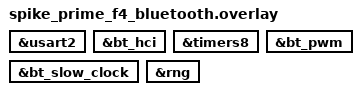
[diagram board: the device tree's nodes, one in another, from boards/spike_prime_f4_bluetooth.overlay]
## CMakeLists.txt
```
# SPDX-License-Identifier: Apache-2.0
cmake_minimum_required(VERSION 3.20.5)

list(APPEND DTS_ROOT ${CMAKE_CURRENT_SOURCE_DIR})
list(APPEND BOARD_ROOT ${CMAKE_CURRENT_SOURCE_DIR})
list(APPEND SYSCALL_INCLUDE_DIRS ${CMAKE_CURRENT_SOURCE_DIR}/sdk/include ${CMAKE_CURRENT_SOURCE_DIR}/include)
find_package(Zephyr REQUIRED HINTS $ENV{ZEPHYR_BASE})
project(brickphyr)
include(cmake/runtime_memory.cmake)

# Zephyr otherwise tracks its own Git index for both version headers.
# Use its application-version dependency hook, including in Git worktrees.
find_package(Git QUIET)
if(GIT_FOUND)
  execute_process(COMMAND ${GIT_EXECUTABLE} rev-parse --path-format=absolute
      --git-path index --git-path HEAD
    WORKING_DIRECTORY ${CMAKE_CURRENT_SOURCE_DIR}
    RESULT_VARIABLE revision_result OUTPUT_VARIABLE revision_dependencies
    OUTPUT_STRIP_TRAILING_WHITESPACE ERROR_QUIET)
  if(revision_result EQUAL 0)
    string(REPLACE "\n" ";" revision_dependencies "${revision_dependencies}")
    set_property(TARGET app_version_h PROPERTY APP_VERSION_DEPENDS ${revision_dependencies})
  endif()
endif()

target_sources(app PRIVATE src/main.c)
target_sources_ifdef(CONFIG_HWINFO app PRIVATE src/hub_reset.c)
target_sources_ifdef(CONFIG_BRICKPHYR_WATCHDOG app PRIVATE src/hub_watchdog.c)
target_sources_ifdef(CONFIG_BRICKPHYR_WATCHDOG_FIXTURE app PRIVATE tests/watchdog/fixture.c)
if(CONFIG_BRICKPHYR_PORTS)
  target_sources(app PRIVATE src/hub_ports.c)
  if(CONFIG_BRICKPHYR_MOTOR_OUTPUT_STM32)
    target_sources(app PRIVATE src/ports/output_stm32.c)
  else()
    target_sources(app PRIVATE src/ports/output.c)
  endif()
  target_include_directories(app PRIVATE ${WEST_TOPDIR}/pybricks-micropython/lib/lego)
endif()
if(CONFIG_BRICKPHYR_PORT_UART)
  target_sources(app PRIVATE src/ports/lump.c src/ports/uart.c src/ports/sensor.c src/ports/settings.c)
  include(cmake/pbio.cmake)
endif()
target_sources_ifdef(CONFIG_BRICKPHYR_BATTERY app PRIVATE src/hub_battery.c)
target_sources_ifdef(CONFIG_BRICKPHYR_CHARGER app PRIVATE src/hub_charger.c)
target_sources_ifdef(CONFIG_BRICKPHYR_USB_BC12 app PRIVATE src/host_usb_power.c)
if(CONFIG_BRICKPHYR_MOTOR_CONTROL)
  set(BRICKPHYR_ROOT ${CMAKE_CURRENT_SOURCE_DIR})
  include(cmake/motor_control.cmake)
endif()
target_sources_ifdef(CONFIG_BRICKPHYR_SOUND_STM32 app PRIVATE drivers/sound_stm32.c)
target_sources_ifdef(CONFIG_BRICKPHYR_CC2640_NPI app PRIVATE drivers/cc2640_npi.c)
if(CONFIG_BRICKPHYR_CC2640_CONTROL)
  include(cmake/cc2640.cmake)
endif()
if(CONFIG_BRICKPHYR_CC2640_BLE)
  include(cmake/pbio.cmake)
  target_sources(app PRIVATE src/host_cc2640.c src/host_ble_session.c
    src/host_transport.c src/host_protocol.c)
endif()
target_sources_ifdef(CONFIG_BRICKPHYR_CC2640_SMP app PRIVATE src/host_cc2640_smp.c)
target_sources_ifdef(CONFIG_BRICKPHYR_SOUND app PRIVATE src/hub_sound.c src/sound/waveform.c)
target_sources_ifdef(CONFIG_BRICKPHYR_MATRIX app PRIVATE src/hub_matrix.c src/hub_matrix_font.c)
target_sources_ifdef(CONFIG_BRICKPHYR_TELEMETRY app PRIVATE src/telemetry.c)
target_include_directories(app PRIVATE include sdk/include)

if(CONFIG_BRICKPHYR_IMU)
  set(BRICKPHYR_ROOT ${CMAKE_CURRENT_SOURCE_DIR})
  include(cmake/hub_imu.cmake)
endif()

if(CONFIG_BRICKPHYR_NATIVE)
  set(BRICKPHYR_ROOT ${CMAKE_CURRENT_SOURCE_DIR})
  include(sdk/native.cmake)
endif()

if(CONFIG_BOARD_SPIKE_PRIME_F4)
  include(cmake/pbio.cmake)
  if(CONFIG_BT_HCI_SETUP)
    target_sources(app PRIVATE drivers/ti_cc2564c.c src/hub_bluetooth.c
      src/host_ble.c src/host_ble_session.c)
    generate_inc_file_for_target(app
      ${WEST_TOPDIR}/modules/lib/ti-bt-service-packs/initscripts/TIInit_6.12.26.bts
      ${ZEPHYR_BINARY_DIR}/include/generated/ti_cc2564c_bts.inc)
  endif()
  target_sources(app PRIVATE src/host_usb.c src/host_transport.c src/host_protocol.c
    ${WEST_TOPDIR}/pybricks-micropython/lib/pbio/src/protocol/pybricks.c
    src/storage.c src/storage_mount.c
    drivers/input_resistor_ladder.c drivers/led_tlc5955.c)
  target_include_directories(app PRIVATE include ${WEST_TOPDIR}/pybricks-micropython/lib/pbio/include)
endif()

if(CONFIG_BRICKPHYR_HUB)
  target_sources(app PRIVATE src/hub.c src/hub_menu.c src/hub_light.c src/hub_power.c src/configuration.c)
  if(CONFIG_BOARD_SPIKE_PRIME_F4 AND CONFIG_BRICKPHYR_APP_STORAGE AND CONFIG_BRICKPHYR_MATRIX)
    target_sources(app PRIVATE src/hub_launcher.c)
  endif()
  add_custom_target(firmware_package
    COMMAND "${PYTHON_EXECUTABLE}" -m tools.package_firmware
            "${ZEPHYR_BINARY_DIR}" --version "${APP_VERSION_STRING}"
            --sdk "${ZEPHYR_SDK_INSTALL_DIR}"
    WORKING_DIRECTORY "${CMAKE_CURRENT_SOURCE_DIR}"
    DEPENDS zephyr_final
    USES_TERMINAL
    VERBATIM
  )
  if(TARGET brickphyr-build-record)
    add_dependencies(firmware_package brickphyr-build-record)
  endif()
endif()
```

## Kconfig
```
# SPDX-License-Identifier: Apache-2.0
mainmenu "Brickphyr"

# Firmware services use queues/events; the native API exposes no mailboxes.
# Do not reserve descriptors for an unused asynchronous mailbox subsystem.
config NUM_MBOX_ASYNC_MSGS
	default 0

# Control preempts storage, which preempts a busy primary. Hardware and management
# retain their priorities above all three; timers can defeat equal-priority slices.
config NUM_PREEMPT_PRIORITIES
	default 17 if BRICKPHYR_NATIVE

# Crypto temporaries share the system heap instead of a user-mapped libc arena.
config TF_PSA_CRYPTO_USER_CONFIG_FILE
	default "brickphyr/crypto_config.h" if BOARD_SPIKE_PRIME_F4 && MBEDTLS_BUILTIN && !MBEDTLS_ENABLE_HEAP

config HEAP_MEM_POOL_ADD_SIZE_BRICKPHYR_CRYPTO
	int
	default 2048 if MBEDTLS && TF_PSA_CRYPTO_USER_CONFIG_FILE = "brickphyr/crypto_config.h"
	default 0

# BC1.2 measures D+/D- before the USB PHY attaches to the host.
config CDC_ACM_SERIAL_ENABLE_AT_BOOT
	default n if BRICKPHYR_USB_BC12

# F4 UART reception cannot tolerate the bytewise size-optimized libc copies
# used by bounded snapshot/record critical sections. Keep firmware code at -Os.
config PICOLIBC_TOOLCHAIN_SPEED_OPTIMIZATIONS
	default y if BOARD_SPIKE_PRIME_F4

# Full source discovery with six controller observations exceeds the upstream
# 384-byte default (about 430 bytes including the SMP header on F4).
config MCUMGR_TRANSPORT_NETBUF_SIZE
	default 512 if BRICKPHYR_MOTOR_CONTROL && BRICKPHYR_TELEMETRY

# Command files use the standard SMP Shell handler on its existing worker.
# Leave room for the response map/header even with a 384-byte SMP buffer.
config SHELL_BACKEND_DUMMY_EXECUTE_ONLY
	default y if MCUMGR_GRP_SHELL

config SHELL_BACKEND_DUMMY_BUF_SIZE
	default 256 if MCUMGR_GRP_SHELL

config MCUMGR_TRANSPORT_NETBUF_USER_DATA_SIZE
	default 16 if BRICKPHYR_CC2640_SMP && 64BIT
	default 8 if BRICKPHYR_CC2640_SMP

# Unknown SMP fields must not bypass the decoder's bounded nesting and exhaust
# its 2 KiB worker stack. Current management fields need no deeper skipped value.
config ZCBOR_MAX_RECURSION_DEPTH
	default 4 if MCUMGR

# Management commands have no acquisition deadline. Keep CBOR/file processing
# below the 833 Hz IMU and 200 Hz motor service, but above Shell/applications.
config MCUMGR_TRANSPORT_WORKQUEUE_THREAD_PRIO
	default 10 if BRICKPHYR_IMU || BRICKPHYR_MOTOR_CONTROL

# Bluetooth needs the cooperative system queue; USB core and CDC processing
# must be preemptible by the 1.2 ms acquisition and 5 ms control work.
config USBD_THREAD_PREEMPTIBLE
	default y if BOARD_SPIKE_PRIME_F4

config USBD_CDC_ACM_WORKQUEUE
	default y if BOARD_SPIKE_PRIME_F4

config USBD_CDC_ACM_WORKQUEUE_PRIORITY
	default 8 if BOARD_SPIKE_PRIME_F4

# Python admission uses about 1 KiB in the GATT callback; the pinned F4 build's
# HCI/L2CAP/ATT call chain adds 696 bytes. Leave room for exception/error paths.
config BT_RX_STACK_SIZE
	default 2048 if BRICKPHYR_PYTHON

config TASK_WDT_MIN_TIMEOUT
	default 1000 if BRICKPHYR_WATCHDOG

config TASK_WDT_HW_FALLBACK_DELAY
	default 1000 if BRICKPHYR_WATCHDOG

config TASK_WDT_CHANNELS
	default 2 if BRICKPHYR_WATCHDOG

source "Kconfig.zephyr"

config BRICKPHYR_HUB
	bool
	default y if BOARD_SPIKE_PRIME_F4 || BOARD_TECHNIC_HUB

config BRICKPHYR_HOST_UART
	bool "UART management stream" if TEST
	depends on UART_INTERRUPT_DRIVEN
	default y if BOARD_SPIKE_PRIME_F4
	help
	  Enable the USB CDC/UART transport for the shared Shell and Pybricks
	  stream dispatcher. BLE management uses the same Shell independently;
	  UART support for wired devices does not require this endpoint.

config BRICKPHYR_CC2640_NPI
	bool "CC2640 SPI network-processor transport"
	depends on DT_HAS_TI_CC2640_NPI_ENABLED
	select GPIO
	select SPI
	select SPI_STM32_INTERRUPT if SOC_FAMILY_STM32
	help
	  Bounded SPI transport for the factory TI BLE stack on Technic Hub.
	  This does not enable advertising or a Bluetooth host endpoint.

config BRICKPHYR_CC2640_CONTROL
	bool "CC2640 controller and peripheral initialization"
	depends on BRICKPHYR_CC2640_NPI
	help
	  Use the TI protocol definitions and Pybricks startup sequence through NPI.
	  Includes peripheral GAP/GATT preparation and ATT handling. Enable
	  BRICKPHYR_CC2640_BLE to start the management endpoint at boot.

config BRICKPHYR_CC2640_BLE
	bool "CC2640 BLE management endpoint"
	depends on BRICKPHYR_CC2640_CONTROL && !BT
	depends on SHELL && MCUMGR_TRANSPORT_SHELL && SETTINGS_RUNTIME
	help
	  Run the factory TI peripheral stack on a dedicated worker and expose
	  the shared Pybricks identity and native Shell/SMP stream. This profile
	  has synthetic transport checks; physical Technic acceptance is pending.

config BRICKPHYR_CC2640_SMP
	bool "CC2640 SMP GATT transport"
	depends on MCUMGR && !BT
	depends on BRICKPHYR_CC2640_BLE || ZTEST
	default y if BRICKPHYR_CC2640_BLE
	select MCUMGR_TRANSPORT_REASSEMBLY
	help
	  Expose the standard MCUmgr BLE service through the factory TI stack.
	  Reuse Zephyr packet reassembly and command processing with the shared
	  management owner. This is independent of SMP over the Shell stream.

config BRICKPHYR_WATCHDOG
	bool "System progress watchdog"
	default y if BRICKPHYR_HUB
	depends on DT_HAS_ST_STM32_WATCHDOG_ENABLED || ARCH_POSIX
	select WATCHDOG
	select TASK_WDT
	select TASK_WDT_HW_FALLBACK
	select HWINFO
	help
	  Supervise initialization, the hub loop and system workqueue using
	  Zephyr Task Watchdog and an independent hardware fallback. The USB
	  powered off state continues supervision until a fresh button press.

config BRICKPHYR_WATCHDOG_TIMEOUT_MS
	int "Maximum interval without system progress (ms)"
	depends on BRICKPHYR_WATCHDOG
	default 3000
	range 100 10000

config BRICKPHYR_WATCHDOG_BOOT_TIMEOUT_MS
	int "Maximum initialization time after watchdog start (ms)"
	depends on BRICKPHYR_WATCHDOG
	default 10000
	range 100 30000

config BRICKPHYR_WATCHDOG_FIXTURE
	bool "Enable one-shot watchdog acceptance commands"
	depends on BRICKPHYR_WATCHDOG && SHELL
	help
	  Diagnostic image only. watchdog_test service stalls the system queue;
	  watchdog_test hardware also locks interrupts until the MCU resets.

config BRICKPHYR_PORTS
	bool "Powered Up port detection"
	default y if BOARD_SPIKE_PRIME_F4
	depends on DT_HAS_LEGO_POWERED_UP_PORTS_ENABLED
	select GPIO
	help
	  Detect empty, passive and UART ports using the Pybricks pin sequence
	  over Zephyr GPIO. The port service also owns sensor supply and coast.

config BRICKPHYR_PORT_UART
	bool "Powered Up UART messaging"
	default y if BOARD_SPIKE_PRIME_F4
	depends on BRICKPHYR_PORTS
	select SERIAL
	select UART_INTERRUPT_DRIVEN
	select UART_USE_RUNTIME_CONFIGURE
	select RING_BUFFER
	select SETTINGS
	select SETTINGS_RUNTIME
	select PINCTRL_NON_STATIC if PINCTRL
	select KERNEL_MEM_POOL
	help
	  Negotiate LUMP devices and acquire raw and converted sensor samples.
	  One worker owns GPIO, UART, measurement selection and recognized sensor
	  DC supply. Raw H-bridge access is not exposed.

config HEAP_MEM_POOL_ADD_SIZE_BRICKPHYR_PORT_UART
	int
	default $(add,2048,$(mul,5888,$(dt_node_enabled_child_count,$(dt_nodelabel_path,hub_ports)))) if BRICKPHYR_PORT_UART && !64BIT && SYS_HEAP_SMALL_ONLY && !SYS_HEAP_CANARIES
	default $(add,2048,$(mul,6144,$(dt_node_enabled_child_count,$(dt_nodelabel_path,hub_ports)))) if BRICKPHYR_PORT_UART
	help
	  UART state and mode descriptions use the shared heap only while a
	  UART device is connected. Budget 5888 bytes per enabled port on a
	  32-bit small heap without canaries: the current ARM link and sixteen
	  complete modes occupy 5760 bytes including allocation headers. Other configurations
	  retain 6 KiB per port. Both include another 2 KiB for negotiation growth.
	  Ordinary devices allocate only their advertised payloads. No allocation
	  occurs on the DATA path.

config BRICKPHYR_MOTORS
	bool "Powered Up direct motor drive"
	default y if BOARD_SPIKE_PRIME_F4
	depends on BRICKPHYR_PORTS
	select PWM
	help
	  Owned, asynchronous native/Shell duty, brake and coast commands through
	  the port service. Outputs stay in coast at boot; application cleanup and
	  device loss stop them.

config BRICKPHYR_MOTOR_CONTROL
	bool "Powered Up speed and position control"
	default y if BOARD_SPIKE_PRIME_F4
	depends on BRICKPHYR_MOTORS && BRICKPHYR_PORT_UART && BRICKPHYR_BATTERY
	help
	  Reuse PBIO models, observer and trajectories in the existing port owner.
	  A dedicated port queue services the 5 ms model step independently of
	  system work. Missing encoder/battery input or a missed frame coasts the
	  motor and reports an error. Physical timing and tuning are experimental.

config BRICKPHYR_MOTOR_OUTPUT_STM32
	bool
	default y if BOARD_SPIKE_PRIME_F4
	depends on BRICKPHYR_MOTORS && SOC_SERIES_STM32F4X
	select PINCTRL
	help
	  Exclusive F4 H-bridge timer backend with shared TIM2 reset/update edges.
	  The generic STM32 PWM driver must not own these timers simultaneously.

config HEAP_MEM_POOL_ADD_SIZE_BRICKPHYR_MOTOR_CONTROL
	int
	default $(mul,512,$(dt_node_enabled_child_count,$(dt_nodelabel_path,hub_ports))) if BRICKPHYR_MOTOR_CONTROL
	help
	  Controller state borrows from the shared heap when observation or
	  regulation is first requested. Budget 512 bytes per enabled port for
	  the controller, observer and allocation overhead. No allocation occurs
	  in control frames; the worker releases state after its lease ends.

config BRICKPHYR_BATTERY
	bool "Battery voltage, load-current and temperature observations"
	default y if BOARD_SPIKE_PRIME_F4 || BOARD_TECHNIC_HUB
	depends on DT_HAS_LEGO_ADC_BATTERY_ENABLED
	select ADC
	select GPIO if $(dt_nodelabel_has_prop,hub_battery,chemistry-gpios)
	select REQUIRES_FULL_LIBC if $(dt_nodelabel_array_prop_has_val,hub_battery,io-channel-names,temperature)
	help
	  Shared native/Shell/SMP snapshots from Zephyr ADC, using the board's
	  Pybricks scaling and optional pack thermistor. No charging control or
	  state-of-charge estimate.

config BRICKPHYR_CHARGER
	bool "Prime hub battery charger"
	default y if BOARD_SPIKE_PRIME_F4
	depends on DT_HAS_LEGO_PRIME_CHARGER_ENABLED
	select ADC
	select PWM
	help
	  MP2639A charging and observations using the shared TLC5955 frame and
	  Pybricks current presets. Standard USB charging requires configuration;
	  dedicated charger detection is a separate USB BC1.2 capability.

config BRICKPHYR_USB_BC12
	bool "USB charger source detection"
	default y if BOARD_SPIKE_PRIME_F4
	depends on BRICKPHYR_CHARGER && USB_BC12
	depends on CDC_ACM_SERIAL_INITIALIZE_AT_BOOT
	help
	  Detect the source before attaching the existing CDC device. The hub
	  power loop handles cable changes, including USB-powered shutdown.

config BRICKPHYR_SOUND
	bool "Hub tone and PCM service"
	default y if BOARD_SPIKE_PRIME_F4
	help
	  One speaker owner, firmware-owned DMA samples and bounded PCM queue.
	  Native applications and the USB/BLE Shell use the same service.

config BRICKPHYR_SOUND_STM32
	bool "Prime F4 DAC sound output"
	default y if BOARD_SPIKE_PRIME_F4
	depends on BRICKPHYR_SOUND
	depends on DT_HAS_LEGO_PRIME_F4_SPEAKER_ENABLED && SOC_SERIES_STM32F4X
	depends on TIMER_HAS_64BIT_CYCLE_COUNTER
	select DMA
	select GPIO
	select PINCTRL
	select RESET
	help
	  Timer-triggered DAC samples through Zephyr DMA. The driver owns DAC1
	  channel 1, TIM6 and the speaker amplifier; no sound starts at boot.

config BRICKPHYR_IMU
	bool "Hub IMU acquisition and orientation"
	default y if BOARD_SPIKE_PRIME_F4
	depends on DT_HAS_ST_LSM6DS3TR_C_ENABLED && TIMER_HAS_64BIT_CYCLE_COUNTER
	select I2C
	select GPIO
	help
	  One bounded worker uses the ST/Pybricks register API and ported
	  calibration/orientation algorithms. Native applications and telemetry
	  share read-only snapshots; calibration uses Zephyr Settings.

config BRICKPHYR_TELEMETRY
	bool "Read-only hub observations"
	default y if BOARD_SPIKE_PRIME_F4
	depends on MCUMGR && SHELL
	select MCUMGR_SMP_CBOR_MIN_DECODING_LEVEL_2
	select MCUMGR_SMP_CBOR_MIN_ENCODING_LEVEL_2 if ZCBOR_CANONICAL
	select MCUMGR_SMP_CBOR_MIN_ENCODING_LEVEL_1
	select CBPRINTF_FP_SUPPORT if BRICKPHYR_PORT_UART
	help
	  On-demand snapshots through SMP and the shared shell. No background
	  transmission, sensor reconfiguration or application lifecycle work.

config BRICKPHYR_MATRIX
	bool "Hub light matrix"
	default y
	depends on DT_HAS_LEGO_HUB_MATRIX_ENABLED && LED
	help
	  Shared 5 by 5 display, with application and terminal ownership.

config BRICKPHYR_LIGHT
	bool "Application access to hub button lighting"
	default y
	depends on (DT_HAS_TI_TLC5955_ENABLED && LED) || (DT_HAS_LEGO_HUB_PWM_RGB_ENABLED && PWM)
	help
	  Shared system indication and application colors on the hub buttons.
	  The base readiness indication remains available without this API.

config BRICKPHYR_NATIVE
	bool "Experimental protected native applications"
	depends on CPU_CORTEX_M && USERSPACE && ARM_MPU && LLEXT
	depends on LLEXT_HEAP_SYSTEM && LLEXT_IMPORT_ALL_GLOBALS
	depends on !CURRENT_THREAD_USE_TLS && !USERSPACE_THREAD_MAY_RAISE_PRIORITY
	depends on LOG && LOG_MODE_DEFERRED
	select LOG_OUTPUT
	select THREAD_STACK_INFO
	select INIT_STACKS
	select THREAD_MONITOR
	select THREAD_NAME
	select SYS_HEAP_RUNTIME_STATS
	select DYNAMIC_THREAD
	select DYNAMIC_THREAD_ALLOC
	help
	  One separately built application, with a compatible versioned SDK.

config BRICKPHYR_APP_PACKAGES
	bool "Composite application packages" if !BRICKPHYR_PYTHON
	depends on (BRICKPHYR_NATIVE || BRICKPHYR_PYTHON) && ZCBOR
	default y
	help
	  Read one file map containing a primary, native controllers and resources.
	  Python requires its file-map reader. Native-only profiles may omit it
	  while retaining standalone ELF applications and the same native ABI.

config BRICKPHYR_CAPTURE
	bool "Built-in finite RAM observations"
	depends on BRICKPHYR_NATIVE && BRICKPHYR_TELEMETRY && SHELL
	default y if BOARD_SPIKE_PRIME_F4 || TEST
	help
	  Record selected passive observations through the shared recorder and SMP.
	  Buffer and sampling stack are allocated only for an explicit capture.
	  With motor support, attach finite grouped actions using the same Shell.
	  Scheduled drive stops on cancellation, failure or management disconnect.

config BRICKPHYR_NATIVE_FIXTURES
	bool "Embed native lifecycle test images"
	depends on BRICKPHYR_NATIVE
	help
	  Board acceptance fixture; not an application upload mechanism.

config LLEXT_EXPORT_SYMBOL_GROUP_BRICKPHYR
	bool
	default y if BRICKPHYR_NATIVE

config BRICKPHYR_APPLICATION_STACK_SIZE
	int "Maximum application stack bytes"
	depends on BRICKPHYR_NATIVE
	default 12288 if BRICKPHYR_PYTHON
	default 2048
	range 2048 32768
	help
	  Admission limit for native ABI requirements and explicit Python stack
	  requests. The default Python stack is configured separately.
	  Stacks are allocated only while an application is loaded, rounded for
	  MPU protection, with a 2048-byte minimum for the native entry/exit path.
	  Python compilation and exception reporting require more stack than the
	  minimal native entry; measure high-water use.

config BRICKPHYR_APPLICATION_IMAGE_SIZE
	int "Maximum uploaded application bytes"
	default 32768
	range 1024 65536
	help
	  Admission limit, not a reservation. A RAM upload also needs this much
	  free system heap alongside the loaded program and its stack.

config BRICKPHYR_NATIVE_MEMORY_SIZE
	int "Native image execution memory limit"
	default 65536
	range 8192 262144
	help
	  Bounds each native image's admitted region and loader metadata cost.
	  Individual allocations use the system heap; loading and stack allocation
	  can still fail if it lacks sufficiently large aligned free blocks.

config BRICKPHYR_PYTHON
	bool "Experimental MicroPython engine"
	depends on BRICKPHYR_NATIVE || (TEST && (ARCH_POSIX || (CPU_CORTEX_M && USERSPACE)))
	depends on ZCBOR
	help
	  MicroPython core with source compilation, bytecode loading and GC.
	  Host integration and Pybricks bindings are under development.

config BRICKPHYR_PYTHON_HEAP_SIZE
	int "Python execution arena bytes"
	depends on BRICKPHYR_PYTHON && BRICKPHYR_NATIVE
	default 65536
	range 8192 262144
	help
	  Allocated from the system heap only while Python runs and released after
	  its thread is joined. Must be a power of two for MPU size/alignment.
	  This does not limit native ELF regions or reserve memory for idle Python.

config BRICKPHYR_PYTHON_STACK_SIZE
	int "Default Python stack bytes"
	depends on BRICKPHYR_PYTHON && BRICKPHYR_NATIVE
	default 12288
	range 4096 BRICKPHYR_APPLICATION_STACK_SIZE
	help
	  Used when a Python launch does not request a stack size. The shared
	  maximum application stack limit still applies to explicit requests.

config BRICKPHYR_PYBRICKS
	bool "Experimental Pybricks Python library"
	depends on BRICKPHYR_PYTHON
	default y
	help
	  Reuse the reference Python bindings over the shared runtime and
	  device services. Current coverage is listed in docs/compatibility.md.

config BRICKPHYR_PYBRICKS_EXECUTION
	bool "Pybricks client execution adapter"
	depends on BRICKPHYR_PYTHON && BRICKPHYR_NATIVE
	default y if BRICKPHYR_PYBRICKS
	help
	  Upload, run, interrupt and exchange application data through the
	  Pybricks USB/BLE protocol. Native SMP, Shell and REPL do not require
	  this adapter. Without it the protocol reports no execution capabilities.

config BRICKPHYR_APP_STORAGE
	bool "Installed native applications in LittleFS"
	depends on BRICKPHYR_NATIVE && FILE_SYSTEM_LITTLEFS && FLASH_MAP
	depends on DT_HAS_FIXED_PARTITIONS_ENABLED
	depends on FILE_SYSTEM_MKFS
	depends on !MCUMGR || MCUMGR_GRP_FS_FILE_ACCESS_HOOK
	select MCUMGR_SMP_VERBOSE_ERR_RESPONSE if MCUMGR

config BRICKPHYR_RADIO
	bool "Application BLE observations"
	depends on BRICKPHYR_NATIVE && BT && BT_PERIPHERAL && BT_OBSERVER
	default y
	help
	  Observe Pybricks broadcasts through the same Zephyr radio as management.
	  Only requested channels allocate storage; applications get copied samples.

config BRICKPHYR_BLE_PEER
	bool "Application BLE peripherals"
	depends on BRICKPHYR_RADIO && BT_CENTRAL && BT_GATT_CLIENT && BT_MAX_CONN >= 2
	default y
	help
	  One LEGO Wireless Protocol v3 or Xbox HID peer alongside management.
	  Discovery and ATT use the existing radio workqueue. Pairing additionally
	  requires BT_SMP; notification buffers are allocated per application lease.

config BRICKPHYR_HUB_NETWORK
	bool "Application Classic hub network"
	depends on BRICKPHYR_RADIO && BT_CLASSIC && BT_MAX_CONN >= 4
	default y
	help
	  Pybricks star networking over Classic L2CAP, alongside BLE management.
	  Kernel-owned per-source inboxes and relay queues are allocated on demand.

config BRICKPHYR_PYBRICKS_SLOTS
	int "Persistent Pybricks program slots"
	depends on BRICKPHYR_PYBRICKS_EXECUTION && BRICKPHYR_APP_STORAGE && SHELL
	range 0 128
	default 5 if BOARD_SPIKE_PRIME_F4
	default 0
	help
	  Map client slots to reserved names in the common application store.
	  They share its free space with named applications. Zero keeps the
	  RAM-only adapter. Native temporary uploads never write this store.
```

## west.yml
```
# SPDX-License-Identifier: Apache-2.0
manifest:
  version: "1.2"
  projects:
    - name: zcbor
      url: https://github.com/alepoydes/zcbor
      revision: f4b3f6975ea28c6f9e664d982710819759816d5b # Bounded unknown-field recursion
      path: modules/lib/zcbor
    - name: ti-bt-service-packs
      url: https://git.ti.com/git/ti-bt/service-packs.git
      revision: 3aa1d75f3c2ae77f6e4d36194e3d281b899ab149
      path: modules/lib/ti-bt-service-packs
    - name: pybricksdev
      url: https://github.com/alepoydes/pybricksdev
      revision: 973fe51b8960c3cac53ce56bed6129f0574c3919
    - name: pybricks
      url: https://github.com/alepoydes/pybricks-micropython
      revision: f3bdff45f3b7521b064e8aa8fb82068323aba880 # Brickphyr integration on v4.1.0b6
      path: pybricks-micropython
      # Initialize only micropython with Git; west recursively fetches unused ports.
    - name: zephyr
      url: https://github.com/alepoydes/zephyr
      revision: 0177626fb33513ca7b18834796c00be27c67c775 # Brickphyr integration on v4.4.2
      import:
        name-allowlist:
          - cmsis_6
          - cmsis-dsp
          - hal_stm32
          - littlefs
          - zcbor
          - mbedtls
          - tf-psa-crypto
  self:
    path: brickphyr
```

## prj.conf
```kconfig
# SPDX-License-Identifier: Apache-2.0
CONFIG_SHELL=y
CONFIG_SHELL_MINIMAL=y
CONFIG_SHELL_HELP=y
CONFIG_SHELL_ARGC_MAX=32
CONFIG_SHELL_BACKEND_SERIAL=y
CONFIG_SHELL_VT100_COLORS=n
CONFIG_SHELL_VT100_COMMANDS=y
CONFIG_SHELL_METAKEYS=y
CONFIG_SHELL_HISTORY=y
CONFIG_SHELL_HISTORY_BUFFER=512
CONFIG_SHELL_TAB=y
CONFIG_SHELL_TAB_AUTOCOMPLETION=y
CONFIG_SHELL_CMDS=y
CONFIG_SHELL_CMDS_RESIZE=y
CONFIG_SHELL_ECHO_STATUS=y
CONFIG_BOOT_BANNER=n
CONFIG_REBOOT=y
```

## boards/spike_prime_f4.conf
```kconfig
# SPDX-License-Identifier: Apache-2.0
# One owner for the CDC data pipe. Shell output never enters the Pybricks stream.
CONFIG_SHELL_BACKEND_SERIAL=n
CONFIG_UART_CONSOLE=n
CONFIG_SHELL_LOG_BACKEND=n
# Diagnostics has one retained sink and no runtime level controls.
CONFIG_LOG_RUNTIME_FILTERING=n
CONFIG_LOG_MAX_LEVEL=2
# Share message packaging code; these warnings/errors are not a hot data path.
CONFIG_LOG_ALWAYS_RUNTIME=y
CONFIG_UART_INTERRUPT_DRIVEN=y
CONFIG_USBD_VREQ_SUPPORT=y
CONFIG_CONSOLE=n
CONFIG_SETTINGS=y
CONFIG_SETTINGS_RUNTIME=y
CONFIG_FLASH=y
CONFIG_FLASH_MAP=y
CONFIG_FLASH_PAGE_LAYOUT=y
CONFIG_FLASH_JESD216_API=y
CONFIG_SPI_NOR_SFDP_RUNTIME=y
CONFIG_SPI_NOR_FLASH_LAYOUT_PAGE_SIZE=4096
CONFIG_FILE_SYSTEM=y
CONFIG_FILE_SYSTEM_LITTLEFS=y
CONFIG_FILE_SYSTEM_MKFS=y
# LittleFS receives caller buffers; Bluetooth crypto uses the shared system heap.
CONFIG_COMMON_LIBC_MALLOC_ARENA_SIZE=0
CONFIG_SETTINGS_FILE=y
CONFIG_SETTINGS_FILE_PATH="/settings/values"
# Boot filesystem work exceeds 1 KiB. Settings compaction nests filesystem
# metadata commits below Shell; give that complete call path a 4 KiB stack.
CONFIG_MAIN_STACK_SIZE=2048
# The 20 ms UI/power loop must yield to 833 Hz IMU acquisition (5) and
# the 5 ms port service (6), including their I/O completion wakeups.
CONFIG_MAIN_THREAD_PRIORITY=7
CONFIG_SHELL_STACK_SIZE=4096
# Observe every DTR edge before the next SET_CONTROL_LINE_STATE can change it.
CONFIG_USBD_MSG_DEFERRED_MODE=n

# Standard SMP framing shares the management stream with the interactive shell.
CONFIG_NET_BUF=y
CONFIG_ZCBOR=y
CONFIG_BASE64=y
CONFIG_CRC=y
CONFIG_MCUMGR=y
CONFIG_SHELL_BACKEND_DUMMY=y
CONFIG_MCUMGR_GRP_SHELL=y
CONFIG_MCUMGR_TRANSPORT_SHELL=y
CONFIG_MCUMGR_GRP_OS=y
CONFIG_MCUMGR_GRP_OS_MCUMGR_PARAMS=y
CONFIG_MCUMGR_GRP_SETTINGS=y
CONFIG_MCUMGR_MGMT_NOTIFICATION_HOOKS=y
CONFIG_MCUMGR_SMP_COMMAND_STATUS_HOOKS=y
CONFIG_MCUMGR_GRP_SETTINGS_ACCESS_HOOK=y
```

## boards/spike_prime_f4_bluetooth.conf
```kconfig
# SPDX-License-Identifier: Apache-2.0
# Optional BLE management; automatically advertises after boot.
CONFIG_BT=y
CONFIG_BT_PERIPHERAL=y
CONFIG_BT_OBSERVER=y
CONFIG_BT_CENTRAL=y
CONFIG_BT_SETTINGS=n
CONFIG_BT_DEVICE_NAME="Brickphyr"
# Full-size HCI commands in TI's service pack.
CONFIG_BT_BUF_CMD_TX_SIZE=255
CONFIG_TEST_RANDOM_GENERATOR=n
CONFIG_ENTROPY_DEVICE_RANDOM_GENERATOR=y
CONFIG_PSA_CSPRNG_GENERATOR=y
# One computer management link and one application LEGO peer.
CONFIG_BT_MAX_CONN=2
CONFIG_BT_SMP=y
# Older LEGO peripherals use LE legacy pairing.
CONFIG_BT_SMP_SC_PAIR_ONLY=n
# Keep both live links' keys; replace unused bonds in RAM for the next peer.
CONFIG_BT_MAX_PAIRED=2
CONFIG_BT_KEYS_OVERWRITE_OLDEST=y
# Fit terminal writes and binary SMP fragments without increasing controller
# packets; Zephyr fragments ATT messages for the CC2564C's 27-byte ACL limit.
CONFIG_BT_GATT_CLIENT=y
CONFIG_BT_GATT_AUTO_UPDATE_MTU=y
CONFIG_BT_L2CAP_TX_MTU=247
CONFIG_BT_BUF_ACL_RX_SIZE=251
# A 244-byte ATT notification needs ten 27-byte ACL fragments on CC2564C,
# queued over successive connection events with the five transmit buffers.
CONFIG_BT_BUF_ACL_TX_COUNT=5
CONFIG_BT_CONN_TX_MAX=5
CONFIG_BT_DATA_LEN_UPDATE=n
# Leave airtime for an application peer beside management traffic. On Inventor
# F4, a 7.5 ms management interval caused Xbox supervision timeouts; 15 ms
# supports simultaneous input and telemetry. Keep peripheral latency zero.
CONFIG_BT_PERIPHERAL_PREF_MIN_INT=12
CONFIG_BT_PERIPHERAL_PREF_MAX_INT=12
CONFIG_BT_PERIPHERAL_PREF_LATENCY=0
# Request the preference immediately if the central initially chooses 7.5 ms.
# Zephyr's default five-second delay exceeds the Xbox's three-second timeout.
CONFIG_BT_CONN_PARAM_UPDATE_TIMEOUT=0
CONFIG_MCUMGR_TRANSPORT_BT=y
# Application peer pairing must not change the existing host management access.
CONFIG_MCUMGR_TRANSPORT_BT_PERM_RW=y
CONFIG_MCUMGR_TRANSPORT_BT_REASSEMBLY=y
# Active SMP and idle links use the same preference. The central still chooses
# the actual interval; SMP must not restore the conflicting 7.5 ms setting.
CONFIG_MCUMGR_TRANSPORT_BT_CONN_PARAM_CONTROL=y
CONFIG_MCUMGR_TRANSPORT_BT_CONN_PARAM_CONTROL_MIN_INT=12
CONFIG_MCUMGR_TRANSPORT_BT_CONN_PARAM_CONTROL_MAX_INT=12
# BLE executes the same Settings/LittleFS path measured above 2 KiB on Shell.
CONFIG_MCUMGR_TRANSPORT_WORKQUEUE_STACK_SIZE=4096
```

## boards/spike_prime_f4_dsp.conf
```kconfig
# SPDX-License-Identifier: Apache-2.0
# Build selected upstream routines for firmware and the optional native SDK.
CONFIG_CMSIS_DSP=y
CONFIG_CMSIS_DSP_FILTERING=y
```

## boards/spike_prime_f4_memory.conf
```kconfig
# SPDX-License-Identifier: Apache-2.0
# Optional diagnostics: Zephyr kernel commands include an immediate reboot.
CONFIG_KERNEL_SHELL=y
CONFIG_SYS_HEAP_RUNTIME_STATS=y
```

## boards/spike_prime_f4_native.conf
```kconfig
# SPDX-License-Identifier: Apache-2.0
CONFIG_ZCBOR=y
CONFIG_BRICKPHYR_NATIVE=y
CONFIG_LLEXT=y
CONFIG_LLEXT_TYPE_ELF_RELOCATABLE=y
CONFIG_LLEXT_HEAP_SYSTEM=y
CONFIG_LLEXT_IMPORT_ALL_GLOBALS=y
CONFIG_LLEXT_EXPORT_DEFAULT_GROUPS=n
CONFIG_LLEXT_EDK_USERSPACE_ONLY=y
# Keep the three dynamic MPU regions for text/constants, data and BSS.
# Native images have no TLS; user entry queries its thread ID through SVC.
CONFIG_CURRENT_THREAD_USE_TLS=n
# F4 SRAM has no reserved prefix; keep static user stacks before ordinary data.
CONFIG_USERSPACE_STACKS_EARLY=y
# Shared by connected-device state, uploads and native loader allocations.
# Fit linked state, including capture/management and the storage worker.
# Python profiles override this shared-heap budget.
CONFIG_HEAP_MEM_POOL_SIZE=221696
# One active request, one queued request and the response retain independent
# buffers. Larger compact blocks reduce BLE request turns for 512 B more pool.
CONFIG_MCUMGR_TRANSPORT_NETBUF_COUNT=3
CONFIG_MCUMGR_TRANSPORT_NETBUF_SIZE=1536
CONFIG_BRICKPHYR_APPLICATION_IMAGE_SIZE=65536
CONFIG_BRICKPHYR_NATIVE_MEMORY_SIZE=214144
CONFIG_BRICKPHYR_APPLICATION_STACK_SIZE=16384
CONFIG_INIT_STACKS=y
CONFIG_THREAD_STACK_INFO=y
# Permission storage covers firmware threads and the protected application.
CONFIG_MAX_THREAD_BYTES=3
CONFIG_MCUMGR_GRP_OS_RESET_HOOK=y
# Essential services must preempt a native busy loop without relying on slices.
CONFIG_SHELL_THREAD_PRIORITY_OVERRIDE=y
CONFIG_SHELL_THREAD_PRIORITY=13
CONFIG_LOG_PROCESS_THREAD_CUSTOM_PRIORITY=y
CONFIG_LOG_PROCESS_THREAD_PRIORITY=13
# Application status includes resource accounting and supported formats.
CONFIG_MCUMGR_SMP_CBOR_MAX_MAIN_MAP_ENTRIES=24
CONFIG_BRICKPHYR_APP_STORAGE=y
# Startup mounts LittleFS and loads user data on the main stack. Keep the
# filesystem-call budget even though saves now run on the storage worker.
CONFIG_MAIN_STACK_SIZE=4096
# ELF validation nests filesystem reads on the SMP worker.
CONFIG_MCUMGR_TRANSPORT_WORKQUEUE_STACK_SIZE=4096
CONFIG_MCUMGR_GRP_FS=y
CONFIG_MCUMGR_GRP_FS_FILE_ACCESS_HOOK=y
```

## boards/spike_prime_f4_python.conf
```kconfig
# SPDX-License-Identifier: Apache-2.0
# Add to the native profile: both engines use the same application supervisor.
CONFIG_BRICKPHYR_PYTHON=y
# Reclaim the former 64 KiB Python reservation and Classic stack capacity into
# the shared heap. Active engines allocate arenas, native regions and stacks
# alongside uploads. The optional Classic fragment sets its smaller budget.
CONFIG_HEAP_MEM_POOL_SIZE=217600
CONFIG_BRICKPHYR_APPLICATION_IMAGE_SIZE=65536
CONFIG_BRICKPHYR_PYTHON_HEAP_SIZE=65536
```

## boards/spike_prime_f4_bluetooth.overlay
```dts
/* SPDX-License-Identifier: Apache-2.0 */
&usart2 { status = "okay"; };
&bt_hci { status = "okay"; };
&timers8 { status = "okay"; };
&bt_pwm { status = "okay"; };
&bt_slow_clock { status = "okay"; };
&rng { status = "okay"; };
```

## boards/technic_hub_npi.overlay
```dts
// SPDX-License-Identifier: Apache-2.0
&bt_reset { status = "disabled"; };
&spi1 { status = "okay"; };
&cc2640 { status = "okay"; };
```

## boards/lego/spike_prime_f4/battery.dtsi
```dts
// SPDX-License-Identifier: Apache-2.0
#include <zephyr/dt-bindings/adc/adc.h>

/* Pybricks prime_hub_f4/platform.c and pbdrvconfig.h at a7b1b04ae.
 * These are physical ADC channels, not PBIO's indices into its DMA buffer.
 */
/ {
	hub_battery: battery {
		compatible = "lego,adc-battery";
		io-channels = <&adc1 10>, <&adc1 11>, <&adc1 8>;
		io-channel-names = "current", "voltage", "temperature";
		chemistry = "li-ion";
		current-full-scale-ma = <7300>;
		voltage-full-scale-mv = <9900>;
		voltage-correction-microohms = <187500>;
	};
};

&adc1 {
	channel@8 {
		reg = <8>;
		zephyr,gain = "ADC_GAIN_1";
		zephyr,reference = "ADC_REF_INTERNAL";
		zephyr,acquisition-time = <ADC_ACQ_TIME(ADC_ACQ_TIME_TICKS, 15)>;
		zephyr,resolution = <12>;
	};
	channel@a {
		reg = <10>;
		zephyr,gain = "ADC_GAIN_1";
		zephyr,reference = "ADC_REF_INTERNAL";
		zephyr,acquisition-time = <ADC_ACQ_TIME(ADC_ACQ_TIME_TICKS, 15)>;
		zephyr,resolution = <12>;
	};
	channel@b {
		reg = <11>;
		zephyr,gain = "ADC_GAIN_1";
		zephyr,reference = "ADC_REF_INTERNAL";
		zephyr,acquisition-time = <ADC_ACQ_TIME(ADC_ACQ_TIME_TICKS, 15)>;
		zephyr,resolution = <12>;
	};
};
```

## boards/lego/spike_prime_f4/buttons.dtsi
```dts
// SPDX-License-Identifier: Apache-2.0

#include <zephyr/dt-bindings/input/input-event-codes.h>
#include <zephyr/dt-bindings/adc/adc.h>

/* Pybricks resistor values and ladder-1 thresholds. With charging disabled,
 * the observed center voltage is 3141..3147, on the ladder-0 cutoff of 3142.
 * Use the nominal ladder cutoffs here; reassess when adding charger control.
 */
/ {
	center_keys: center-keys {
		compatible = "lego,resistor-ladder";
		io-channels = <&adc1 14>;
		thresholds = <3872 3394 3009 2755 2538 2327 2141 1969>;
		key-codes = <0 INPUT_KEY_ENTER 0>;
	};
	arrow_keys: arrow-keys {
		compatible = "lego,resistor-ladder";
		io-channels = <&adc1 1>;
		thresholds = <3872 3394 3009 2755 2538 2327 2141 1969>;
		key-codes = <INPUT_KEY_LEFT INPUT_KEY_RIGHT INPUT_KEY_BLUETOOTH>;
	};
};

&adc1 {
	#address-cells = <1>;
	#size-cells = <0>;

	channel@1 {
		reg = <1>;
		zephyr,gain = "ADC_GAIN_1";
		zephyr,reference = "ADC_REF_INTERNAL";
		zephyr,acquisition-time = <ADC_ACQ_TIME(ADC_ACQ_TIME_TICKS, 15)>;
		zephyr,resolution = <12>;
	};
	channel@e {
		reg = <14>;
		zephyr,gain = "ADC_GAIN_1";
		zephyr,reference = "ADC_REF_INTERNAL";
		zephyr,acquisition-time = <ADC_ACQ_TIME(ADC_ACQ_TIME_TICKS, 15)>;
		zephyr,resolution = <12>;
	};
};
```

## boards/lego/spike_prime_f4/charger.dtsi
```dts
// SPDX-License-Identifier: Apache-2.0
/ {
	hub_charger: charger {
		compatible = "lego,prime-charger";
		mode-controller = <&hub_leds>;
		mode-channel = <14>;
		pwms = <&charger_pwm 1 10417 PWM_POLARITY_NORMAL>;
		io-channels = <&adc1 3>;
		status-ladder = <&center_keys>;
		status-bit = <2>;
	};
};

&timers5 {
	status = "okay";
	charger_pwm: pwm {
		pinctrl-0 = <&tim5_ch1_pa0>;
		pinctrl-names = "default";
		status = "okay";
	};
};

&adc1 {
	channel@3 {
		reg = <3>;
		zephyr,gain = "ADC_GAIN_1";
		zephyr,reference = "ADC_REF_INTERNAL";
		zephyr,acquisition-time = <ADC_ACQ_TIME(ADC_ACQ_TIME_TICKS, 15)>;
		zephyr,resolution = <12>;
	};
};
```

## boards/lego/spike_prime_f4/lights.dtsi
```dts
/* SPDX-License-Identifier: Apache-2.0 */
/ {
	hub_matrix: matrix {
		compatible = "lego,hub-matrix";
		led-controller = <&hub_leds>;
		/* Pybricks prime_hub_f4 LED_ARRAY_DEV_0_LIGHT_MATRIX wiring. */
		channels = <38 36 41 46 33
			    37 28 39 47 21
			    24 29 31 45 23
			    26 27 32 34 22
			    25 40 30 35 9>;
	};
};
&hub_leds {
	/* Provisional gains from visual RGB-pair checks on Inventor F4. */
	white-balance = <255 47 64>;
	status_top: status-top { channels = <5 4 3>; };
	status_bottom: status-bottom { channels = <8 7 6>; };
	bluetooth_led: bluetooth { channels = <20 19 18>; };
};
```

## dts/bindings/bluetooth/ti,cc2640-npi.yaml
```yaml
# SPDX-License-Identifier: Apache-2.0
description: TI CC2640 factory network processor using SPI NPI
compatible: "ti,cc2640-npi"
include: spi-device.yaml
properties:
  reset-gpios:
    type: phandle-array
    required: true
    description: Active-low reset, released to input after the startup pulse
  mrdy-gpios:
    type: phandle-array
    required: true
    description: Active-low host ready output
  srdy-gpios:
    type: phandle-array
    required: true
    description: Active-low controller ready input with pull-up and both-edge IRQ
```

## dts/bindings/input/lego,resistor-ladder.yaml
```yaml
# SPDX-License-Identifier: Apache-2.0
# Thresholds use the Pybricks three-input resistor-ladder decoder.
description: LEGO three-input resistor ladder
compatible: "lego,resistor-ladder"
include: base.yaml
properties:
  io-channels:
    type: phandle-array
    required: true
  thresholds:
    type: array
    required: true
    description: Eight descending thresholds in raw 12-bit ADC counts.
  key-codes:
    type: array
    required: true
    description: Three input codes in resistor order; zero skips a non-button input.
  sample-period-ms:
    type: int
    default: 10
```

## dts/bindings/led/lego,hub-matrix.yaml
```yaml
# SPDX-License-Identifier: Apache-2.0
description: LEGO hub 5 by 5 monochrome matrix on a shared TLC5955
compatible: "lego,hub-matrix"
properties:
  led-controller:
    type: phandle
    required: true
  channels:
    type: array
    required: true
    description: 25 TLC5955 wire channel indices, row-major in the hub's upright orientation.
```

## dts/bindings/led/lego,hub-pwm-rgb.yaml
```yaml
# SPDX-License-Identifier: Apache-2.0
description: Hub status RGB light driven by three timer PWM channels
compatible: "lego,hub-pwm-rgb"
include: base.yaml
properties:
  pwms:
    type: phandle-array
    required: true
    description: Red, green and blue channels, in that order
  white-balance:
    type: array
    required: true
    description: Linear red, green and blue PWM weights, each from 0 to 255
```

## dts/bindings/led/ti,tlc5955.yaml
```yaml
# SPDX-License-Identifier: Apache-2.0
description: TI TLC5955 LED controller with an external grayscale clock
compatible: "ti,tlc5955"
include: spi-device.yaml
properties:
  white-balance:
    type: array
    description: RGB duty weights (0..255) for the attached LEDs at logical white.
  latch-gpios:
    type: phandle-array
    required: true
  pwms:
    type: phandle-array
    required: true
    description: External GSCLK; the period must be exactly representable by the timer.
  initial-full-channels:
    type: array
    description: Non-LED channels initialized at full duty and reserved from LED writes.
child-binding:
  properties:
    channels:
      type: array
      required: true
      description: RGB channel indices in the Pybricks wire ordering (0..47).
```

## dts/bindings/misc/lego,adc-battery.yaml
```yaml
# SPDX-License-Identifier: Apache-2.0
description: LEGO battery voltage, load current and optional 103AT thermistor
compatible: "lego,adc-battery"
include: base.yaml
properties:
  io-channels:
    required: true
  io-channel-names:
    required: true
    description: Separate 12-bit inputs named current and voltage, and optional temperature.
  chemistry:
    type: string
    required: true
    enum: [unknown, alkaline, li-ion]
    description: Fixed battery chemistry; use unknown when chemistry-gpios selects it.
  chemistry-gpios:
    type: phandle-array
    description: Optional connector input sampled at boot; active means alkaline, inactive Li-ion.
  current-raw-offset:
    type: int
    default: 0
    description: Nonnegative 12-bit offset added before scaling load current.
  current-full-scale-ma:
    type: int
    required: true
    description: Milliamps corresponding to 4096 ADC counts.
  voltage-full-scale-mv:
    type: int
    required: true
    description: Millivolts corresponding to 4096 ADC counts.
  voltage-correction-microohms:
    type: int
    required: true
    description: Measurement-path resistance compensated using measured current.
```

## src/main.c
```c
// SPDX-License-Identifier: Apache-2.0
#include "hub_sound.h"
#include "hub_ports.h"

#include <inttypes.h>
#include <string.h>
#include <errno.h>
#ifdef CONFIG_BRICKPHYR_NATIVE
#include "application.h"
#endif
#ifdef CONFIG_BRICKPHYR_HUB
#include "hub.h"
#endif
#include <zephyr/app_version.h>
#include <zephyr/kernel.h>
#include <zephyr/shell/shell.h>
#include <zephyr/sys/reboot.h>
#include <zephyr/sys/util.h>
#include <zephyr/version.h>

static int cmd_info(const struct shell *shell, size_t argc, char **argv)
{
	shell_print(shell, "Brickphyr %s (%s)", APP_VERSION_STRING, STRINGIFY(APP_BUILD_VERSION));
	shell_print(shell, "Zephyr %s", KERNEL_VERSION_STRING);
	shell_print(shell, "Target %s", CONFIG_BOARD_TARGET);
	return 0;
}

static int cmd_uptime(const struct shell *shell, size_t argc, char **argv)
{
	shell_print(shell, "Uptime: %" PRId64 " ms", k_uptime_get());
	return 0;
}

static int cmd_reboot(const struct shell *shell, size_t argc, char **argv)
{
	if (argc == 2) {
		if (strcmp(argv[1], "dfu")) {
			shell_error(shell, "Usage: reboot [dfu]");
			return -EINVAL;
		}
#ifdef CONFIG_BRICKPHYR_HUB
		int err = hub_reboot_dfu();
		shell_error(shell, "DFU entry failed: %d", err);
		return err;
#else
		shell_error(shell, "DFU is not supported on this target.");
		return -ENOTSUP;
#endif
	}
	/* Do not wait for a terminal to drain output before resetting the board. */
#ifdef CONFIG_BRICKPHYR_NATIVE
	int err = application_shutdown();
	if (err) {
		return err;
	}
#endif
	int sound_error = hub_sound_shutdown();
	if (sound_error) {
		return sound_error;
	}
	int port_error = hub_ports_shutdown();
	if (port_error) {
		return port_error;
	}
	sys_reboot(SYS_REBOOT_COLD);
	return 0;
}

SHELL_CMD_ARG_REGISTER(info, NULL, "Firmware version and build target.", cmd_info, 1, 0);
SHELL_CMD_ARG_REGISTER(uptime, NULL, "Monotonic time since boot, in milliseconds.", cmd_uptime, 1, 0);
SHELL_CMD_ARG_REGISTER(reboot, NULL, "Restart the firmware, or enter the existing DFU loader: reboot [dfu].", cmd_reboot, 1, 1);

int main(void)
{
#ifdef CONFIG_BRICKPHYR_HUB
	hub_run();
#endif
	/* Shell and USB run in their own threads; boot never waits for a host. */
	return 0;
}
```

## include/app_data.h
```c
// SPDX-License-Identifier: Apache-2.0
#pragma once
#include <stddef.h>
#include <stdint.h>

/* Initialize after mounting the common application store, preserving its error. */
void app_data_load(int storage_error);
/* Shared user data in RAM; no filesystem access or waiting in read/write. */
int app_data_read(uint32_t offset, void *data, size_t size);
int app_data_write(uint32_t offset, const void *data, size_t size);
/* Copy a snapshot and submit it without waiting. Positive request or errno;
 * only one pending request. It survives application exit and disconnect. */
int app_data_save_start(void);
/* Latest request: EINPROGRESS, success or stored error; ESTALE after a newer
 * accepted request. No waiting or filesystem access. */
int app_data_save_status(uint32_t request);
/* Firmware threads only: wait for prior work, then save the current snapshot. */
int app_data_save(void);
```

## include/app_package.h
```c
// SPDX-License-Identifier: Apache-2.0
#pragma once

#include <stddef.h>
#include "application.h"

#define APP_PATH_LIMIT 128
#define APP_FILE_LIMIT 64

/* Exact, bounded reads from an immutable package. The owner keeps the backing
 * RAM or file alive; readers retain offsets, never pointers into that backing. */
struct app_source {
	int (*read)(void *context, size_t offset, void *data, size_t length);
	void *context;
	size_t length;
};

struct app_resource {
	size_t offset, length;
};

enum app_resource_type { APP_RESOURCE_MISSING, APP_RESOURCE_FILE, APP_RESOURCE_DIR };

int app_source_read(const struct app_source *source, size_t offset, void *data, size_t length);
int app_source_memory(void *context, size_t offset, void *data, size_t length);
struct app_package_info {
	enum application_format format;
	char entry[APP_PATH_LIMIT + 1];
};

/* FILES denotes ordinary data; executable envelopes use NATIVE/PYTHON/MPY.
 * Validation reads bounded ranges and does not link or execute components. */
typedef int (*app_package_check_fn)(const struct app_source *source,
	struct app_resource file, enum application_format format);
int app_package_check(const struct app_source *source, app_package_check_fn check,
	struct app_package_info *info);
/* Return a resource type or the original I/O error. The empty path is the root;
 * the empty CBOR key is entry metadata, not a readable file. */
int app_package_find(const struct app_source *source, const char *path, struct app_resource *file);
int app_package_entry(const struct app_source *source, char *path, size_t capacity);
```

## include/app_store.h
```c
// SPDX-License-Identifier: Apache-2.0
#pragma once
#include <stddef.h>

struct k_mutex;
extern struct k_mutex store_lock;
/* Caller owns store_lock. Resolve the common installed namespace. */
int app_store_path(const char *name, char *path, size_t capacity);

#define APP_NAME_MAX 32
#define APP_STAGE "/apps/.incoming"
struct app_file {
	char name[APP_NAME_MAX + 1];
	size_t size;
};

int app_store_status(void);
int app_store_format(void);
/* Lexical pagination; an empty returned name ends iteration. */
int app_store_next(const char *after, struct app_file *entry, size_t *available);
/* Browse visible named programs with -1, 0 or +1. Zero retains current if present,
 * otherwise chooses the next name; an empty current starts at the first.
 * The other directions wrap at the ends. */
int app_store_browse(const char *current, int direction, struct app_file *entry);
/* Stop/join the app, remove abandoned staging and the named previous package. */
int app_store_prepare_install(const char *name);
int app_store_remove(const char *name);
/* Called by the serial SMP dispatcher, after closing its standard FS transfer. */
int app_store_publish(const char *name, size_t length);
/* Install the common validated RAM upload; also owns reserved @0..@127 slots. */
int app_store_publish_upload(const char *name);
int app_store_run(const char *name, size_t stack_size);
struct application_budget_request;
struct application_budget;
int app_store_budget(const char *name, const struct application_budget_request *request,
	struct application_budget *budget);
```

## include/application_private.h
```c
// SPDX-License-Identifier: Apache-2.0
#pragma once
#include <zephyr/toolchain.h>
#include <zephyr/syscall.h>
__syscall void application_finished(int result);
#ifdef CONFIG_BRICKPHYR_PYTHON
/* Zero capacity observes pending bytes without consuming them. */
__syscall int application_stdin(void *data, size_t capacity);
/* Attached stream: return bytes accepted, zero when full; detached: consume into
 * the counted log. Zero length observes writable status without emitting bytes. */
__syscall int application_stdout(const void *data, size_t length);
/* Wake on input, output space, attachment, interrupt or timeout; -1 waits. */
__syscall int application_event_wait(int32_t timeout_ms);
/* One copied AppData mailbox, separate from standard input/output. Tokens bind
 * reads, finalizers and asynchronous completion to the originating object. */
#define APPLICATION_MESSAGE_RX_MAX 1024
#define APPLICATION_MESSAGE_TX_MAX 63
__syscall int application_message_open(size_t capacity);
__syscall int application_message_close(uint32_t lease);
__syscall int application_message_read(uint32_t lease, size_t offset, void *data, size_t length);
__syscall int application_message_send(uint32_t lease, const void *data, size_t length);
__syscall int application_message_status(uint32_t lease, uint32_t request);
__syscall int application_message_cancel(uint32_t lease, uint32_t request);
/* Exact reads from this application's immutable source, serviced below control
 * priority. The kernel validates every offset and destination. */
__syscall int application_source_read(size_t offset, void *data, size_t length);

/* One pending code reservation; commit(NULL, 0) cancels it after a loader error. */
__syscall intptr_t application_code_reserve(size_t length);
__syscall int application_code_commit(const void *data, size_t length);
#endif
#include <zephyr/syscalls/application_private.h>
```

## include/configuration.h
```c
// SPDX-License-Identifier: Apache-2.0
#pragma once

#include <stdbool.h>
#include <stddef.h>
#include <stdint.h>

/* Presentation of little-endian 32-bit Settings values. The owning Settings
 * handler alone validates and applies them; this is not another value store. */
struct config_entry {
	const char *name;
	const char *unit;
	size_t count;
	bool is_signed;
};

#define CONFIG_VALUE_BYTES (6 * sizeof(uint32_t))
extern const struct config_entry power_config[2];
extern const struct config_entry imu_config[6];

int config_index(const struct config_entry *entries, size_t count, const char *name);
int config_load(const struct config_entry *entries, size_t count);
int config_export(const struct config_entry *entries, size_t count,
	int (*save)(const char *, const void *, size_t));
/* Trusted synchronous save. Application callers use the queued operation. */
int config_save(void);
int config_save_start(void);
int config_save_status(uint32_t request);
/* Shutdown waits only for an explicitly requested save; it does not start one. */
int config_save_finish(void);
```

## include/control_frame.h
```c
// SPDX-License-Identifier: Apache-2.0
#pragma once
#include <stdbool.h>
#include <brickphyr_control.h>

int control_frame_get(uint32_t port_mask, struct bp_control_frame *frame);
int control_frame_imu_wait(uint32_t port_mask, uint32_t sequence, bool previous,
	uint32_t timeout_ms, struct bp_control_frame *frame);
```
